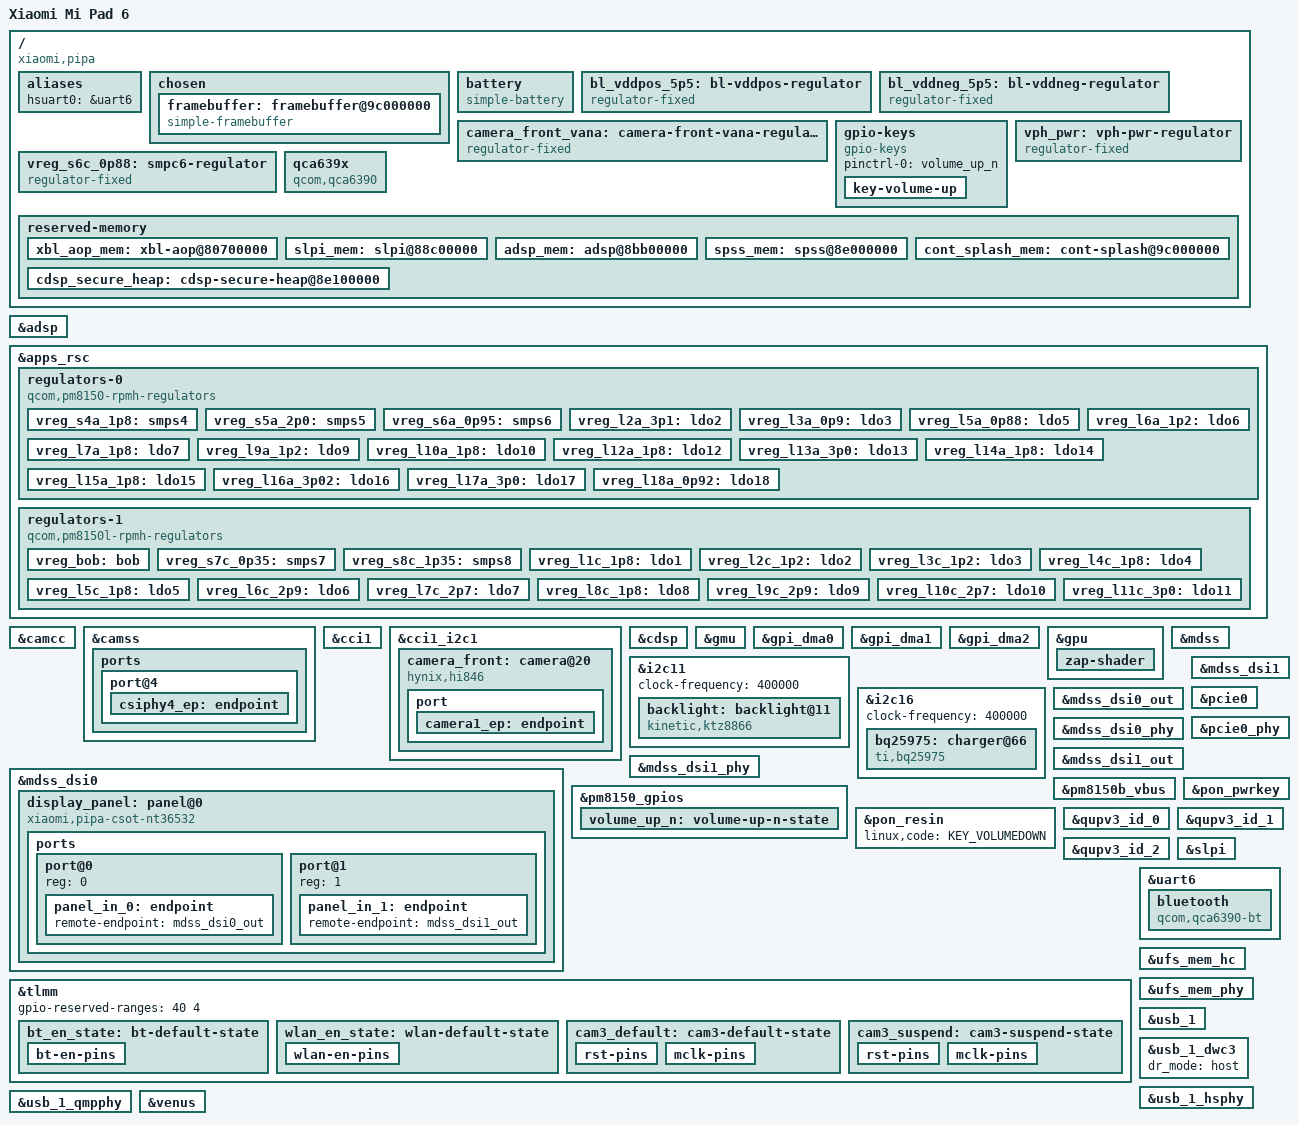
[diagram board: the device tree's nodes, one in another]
/dts-v1/;

#include <dt-bindings/arm/qcom,ids.h>
#include <dt-bindings/phy/phy.h>
#include <dt-bindings/regulator/qcom,rpmh-regulator.h>
#include <dt-bindings/usb/pd.h>
#include "sm8250ac.dtsi"
#include "pm8150.dtsi"
#include "pm8150b.dtsi"
#include "pm8150l.dtsi"

/*
 * Delete following upstream (sm8250.dtsi) reserved
 * memory mappings which are different on this device.
 */
/delete-node/ &adsp_mem;
/delete-node/ &cdsp_secure_heap;
/delete-node/ &slpi_mem;
/delete-node/ &spss_mem;
/delete-node/ &xbl_aop_mem;

/ {
	model = "Xiaomi Mi Pad 6";
	compatible = "xiaomi,pipa", "qcom,sm8250";
	classis-type = "tablet";

	/* required for bootloader to select correct board */
	qcom,msm-id = <QCOM_ID_SM8250 0x20001>; /* SM8250 v2.1 */
	qcom,board-id = <0x34 0>;

	aliases {
		hsuart0 = &uart6;
	};

	chosen {
		#address-cells = <2>;
		#size-cells = <2>;
		ranges;

		framebuffer: framebuffer@9c000000 {
			compatible = "simple-framebuffer";
			reg = <0x0 0x9c000000 0x0 0x2300000>;
			width = <1800>;
			height = <2880>;
			stride = <(1800 * 4)>;
			format = "a8r8g8b8";
		};
	};

	battery: battery {
		compatible = "simple-battery";
		device-chemistry = "lithium-ion-polymer";
		// voltage-min-design-microvolt = <3870000>;
		// energy-full-design-microwatt-hours = <16600000>;
		// charge-full-design-microamp-hours = <4300000>;
		constant-charge-current-max-microamp = <5900000>;
		constant-charge-voltage-max-microvolt = <4430000>;
	};

	bl_vddpos_5p5: bl-vddpos-regulator {
		compatible = "regulator-fixed";
		regulator-name = "bl_vddpos_5p5";
		regulator-min-microvolt = <5500000>;
		regulator-max-microvolt = <5500000>;
		regulator-enable-ramp-delay = <233>;
		gpio = <&tlmm 130 GPIO_ACTIVE_HIGH>;
		enable-active-high;
		regulator-boot-on;
	};

	bl_vddneg_5p5: bl-vddneg-regulator {
		compatible = "regulator-fixed";
		regulator-name = "bl_vddneg_5p5";
		regulator-min-microvolt = <5500000>;
		regulator-max-microvolt = <5500000>;
		regulator-enable-ramp-delay = <233>;
		gpio = <&tlmm 131 GPIO_ACTIVE_HIGH>;
		enable-active-high;
		regulator-boot-on;
	};

    camera_front_vana: camera-front-vana-regulator {
        compatible = "regulator-fixed";
        regulator-name = "camera_front_vana";
        regulator-min-microvolt = <2800000>;
        regulator-max-microvolt = <2800000>;
        regulator-enable-ramp-delay = <135>;
        enable-active-high;
        gpio = <&tlmm 84 0>;
    };

	gpio-keys {
		compatible = "gpio-keys";

		pinctrl-0 = <&volume_up_n>;
		pinctrl-names = "default";

		key-volume-up {
			label = "Volume Up";
			linux,code = <KEY_VOLUMEUP>;
			gpios = <&pm8150_gpios 6 GPIO_ACTIVE_LOW>;
			debounce-interval = <15>;
			linux,can-disable;
			wakeup-source;
		};
	};

	vph_pwr: vph-pwr-regulator {
		compatible = "regulator-fixed";
		regulator-name = "vph_pwr";
		regulator-min-microvolt = <3700000>;
		regulator-max-microvolt = <3700000>;
	};

	/* S6c is really ebi.lvl but it's there for supply map completeness sake. */
	vreg_s6c_0p88: smpc6-regulator {
		compatible = "regulator-fixed";
		regulator-name = "vreg_s6c_0p88";
		regulator-min-microvolt = <880000>;
		regulator-max-microvolt = <880000>;
		regulator-always-on;
		vin-supply = <&vph_pwr>;
	};

	qca639x: qca639x {
		compatible = "qcom,qca6390";
		#power-domain-cells = <0>;

		vddaon-supply = <&vreg_s6a_0p95>;
		vddpmu-supply = <&vreg_s6a_0p95>;
		vddrfa1-supply = <&vreg_s5a_2p0>;
		vddrfa2-supply = <&vreg_s8c_1p35>;
		vddrfa3-supply = <&vreg_s5a_2p0>;
		vddpcie1-supply = <&vreg_s8c_1p35>;
		vddpcie2-supply = <&vreg_s5a_2p0>;
		vddio-supply = <&vreg_s4a_1p8>;

		pinctrl-names = "default";
		pinctrl-0 = <&wlan_en_state>;

		wlan-en-gpios = <&tlmm 20 GPIO_ACTIVE_HIGH>;
	};

	reserved-memory {
		xbl_aop_mem: xbl-aop@80700000 {
			reg = <0x0 0x80600000 0x0 0x260000>;
			no-map;
		};

		slpi_mem: slpi@88c00000 {
			reg = <0x0 0x88c00000 0x0 0x2f00000>;
			no-map;
		};

		adsp_mem: adsp@8bb00000 {
			reg = <0x0 0x8bb00000 0x0 0x2500000>;
			no-map;
		};

		spss_mem: spss@8e000000 {
			reg = <0x0 0x8e000000 0x0 0x100000>;
			no-map;
		};

		cdsp_secure_heap: cdsp-secure-heap@8e100000 {
			reg = <0x0 0x8e100000 0x0 0x4600000>;
			no-map;
		};

		cont_splash_mem: cont-splash@9c000000 {
			reg = <0x0 0x9c000000 0x0 0x2300000>;
			no-map;
		};
	};
};

&adsp {
	firmware-name = "qcom/sm8250/xiaomi/pipa/adsp.mbn";
	status = "okay";
};

&apps_rsc {
	regulators-0 {
		compatible = "qcom,pm8150-rpmh-regulators";
		qcom,pmic-id = "a";

		vdd-s1-supply = <&vph_pwr>;
		vdd-s2-supply = <&vph_pwr>;
		vdd-s3-supply = <&vph_pwr>;
		vdd-s4-supply = <&vph_pwr>;
		vdd-s5-supply = <&vph_pwr>;
		vdd-s6-supply = <&vph_pwr>;
		vdd-s7-supply = <&vph_pwr>;
		vdd-s8-supply = <&vph_pwr>;
		vdd-s9-supply = <&vph_pwr>;
		vdd-s10-supply = <&vph_pwr>;
		vdd-l1-l8-l11-supply = <&vreg_s6c_0p88>;
		vdd-l2-l10-supply = <&vreg_bob>;
		vdd-l3-l4-l5-l18-supply = <&vreg_s6a_0p95>;
		vdd-l6-l9-supply = <&vreg_s8c_1p35>;
		vdd-l7-l12-l14-l15-supply = <&vreg_s5a_2p0>;
		vdd-l13-l16-l17-supply = <&vreg_bob>;

		/* (S1+S2+S3) - cx.lvl (ARC) */

		vreg_s4a_1p8: smps4 {
			regulator-name = "vreg_s4a_1p8";
			regulator-min-microvolt = <1800000>;
			regulator-max-microvolt = <1920000>;
			regulator-initial-mode = <RPMH_REGULATOR_MODE_HPM>;
			regulator-allow-set-load;
			regulator-allowed-modes = <RPMH_REGULATOR_MODE_LPM
						   RPMH_REGULATOR_MODE_HPM>;
		};

		vreg_s5a_2p0: smps5 {
			regulator-name = "vreg_s5a_2p0";
			regulator-min-microvolt = <2000000>;
			regulator-max-microvolt = <2040000>;
			regulator-initial-mode = <RPMH_REGULATOR_MODE_HPM>;
		};

		vreg_s6a_0p95: smps6 {
			regulator-name = "vreg_s6a_0p95";
			regulator-min-microvolt = <600000>;
			regulator-max-microvolt = <1128000>;
			regulator-initial-mode = <RPMH_REGULATOR_MODE_HPM>;
		};

		vreg_l2a_3p1: ldo2 {
			regulator-name = "vreg_l2a_3p1";
			regulator-min-microvolt = <3072000>;
			regulator-max-microvolt = <3072000>;
			regulator-initial-mode = <RPMH_REGULATOR_MODE_HPM>;
		};

		vreg_l3a_0p9: ldo3 {
			regulator-name = "vreg_l3a_0p9";
			regulator-min-microvolt = <928000>;
			regulator-max-microvolt = <932000>;
			regulator-initial-mode = <RPMH_REGULATOR_MODE_HPM>;
		};

		/* L4 - lmx.lvl (ARC) */

		vreg_l5a_0p88: ldo5 {
			regulator-name = "vreg_l5a_0p88";
			regulator-min-microvolt = <880000>;
			regulator-max-microvolt = <880000>;
			regulator-initial-mode = <RPMH_REGULATOR_MODE_HPM>;
		};

		vreg_l6a_1p2: ldo6 {
			regulator-name = "vreg_l6a_1p2";
			regulator-min-microvolt = <1200000>;
			regulator-max-microvolt = <1200000>;
			regulator-initial-mode = <RPMH_REGULATOR_MODE_HPM>;
			regulator-allow-set-load;
			regulator-allowed-modes = <RPMH_REGULATOR_MODE_LPM
						   RPMH_REGULATOR_MODE_HPM>;
		};

		vreg_l7a_1p8: ldo7 {
			regulator-name = "vreg_l7a_1p8";
			regulator-min-microvolt = <1704000>;
			regulator-max-microvolt = <1800000>;
			regulator-initial-mode = <RPMH_REGULATOR_MODE_HPM>;
		};

		vreg_l9a_1p2: ldo9 {
			regulator-name = "vreg_l9a_1p2";
			regulator-min-microvolt = <1200000>;
			regulator-max-microvolt = <1200000>;
			regulator-initial-mode = <RPMH_REGULATOR_MODE_HPM>;
		};

		vreg_l10a_1p8: ldo10 {
			regulator-name = "vreg_l10a_1p8";
			regulator-min-microvolt = <1800000>;
			regulator-max-microvolt = <2960000>;
			regulator-initial-mode = <RPMH_REGULATOR_MODE_HPM>;
		};

		/* L11 - lcx.lvl (ARC) */

		vreg_l12a_1p8: ldo12 {
			regulator-name = "vreg_l12a_1p8";
			regulator-min-microvolt = <1800000>;
			regulator-max-microvolt = <1800000>;
			regulator-initial-mode = <RPMH_REGULATOR_MODE_HPM>;
		};

		vreg_l13a_3p0: ldo13 {
			regulator-name = "vreg_l13a_3p0";
			regulator-min-microvolt = <3008000>;
			regulator-max-microvolt = <3008000>;
			regulator-initial-mode = <RPMH_REGULATOR_MODE_HPM>;
		};

		vreg_l14a_1p8: ldo14 {
			regulator-name = "vreg_l14a_1p8";
			regulator-min-microvolt = <1800000>;
			regulator-max-microvolt = <1880000>;
			regulator-initial-mode = <RPMH_REGULATOR_MODE_HPM>;
		};

		vreg_l15a_1p8: ldo15 {
			regulator-name = "vreg_l15a_1p8";
			regulator-min-microvolt = <1800000>;
			regulator-max-microvolt = <1800000>;
			regulator-initial-mode = <RPMH_REGULATOR_MODE_HPM>;
		};

		vreg_l16a_3p02: ldo16 {
			regulator-name = "vreg_l16a_3p02";
			regulator-min-microvolt = <3024000>;
			regulator-max-microvolt = <3304000>;
			regulator-initial-mode = <RPMH_REGULATOR_MODE_HPM>;
		};

		vreg_l17a_3p0: ldo17 {
			regulator-name = "vreg_l17a_3p0";
			regulator-min-microvolt = <2496000>;
			regulator-max-microvolt = <3008000>;
			regulator-initial-mode = <RPMH_REGULATOR_MODE_HPM>;
			regulator-allow-set-load;
			regulator-allowed-modes = <RPMH_REGULATOR_MODE_LPM
						   RPMH_REGULATOR_MODE_HPM>;
		};

		vreg_l18a_0p92: ldo18 {
			regulator-name = "vreg_l18a_0p92";
			regulator-min-microvolt = <800000>;
			regulator-max-microvolt = <920000>;
			regulator-initial-mode = <RPMH_REGULATOR_MODE_HPM>;
		};
	};

	regulators-1 {
		compatible = "qcom,pm8150l-rpmh-regulators";
		qcom,pmic-id = "c";

		vdd-s1-supply = <&vph_pwr>;
		vdd-s2-supply = <&vph_pwr>;
		vdd-s3-supply = <&vph_pwr>;
		vdd-s4-supply = <&vph_pwr>;
		vdd-s5-supply = <&vph_pwr>;
		vdd-s6-supply = <&vph_pwr>;
		vdd-s7-supply = <&vph_pwr>;
		vdd-s8-supply = <&vph_pwr>;
		vdd-l1-l8-supply = <&vreg_s4a_1p8>;
		vdd-l2-l3-supply = <&vreg_s8c_1p35>;
		vdd-l4-l5-l6-supply = <&vreg_bob>;
		vdd-l7-l11-supply = <&vreg_bob>;
		vdd-l9-l10-supply = <&vreg_bob>;
		vdd-bob-supply = <&vph_pwr>;

		vreg_bob: bob {
			regulator-name = "vreg_bob";
			regulator-min-microvolt = <3008000>;
			regulator-max-microvolt = <3960000>;
			regulator-initial-mode = <RPMH_REGULATOR_MODE_AUTO>;
		};

		/*
		 * S1-S6 are ARCs:
		 * (S1+S2) - gfx.lvl,
		 * S3 - mx.lvl,
		 * (S4+S5) - mmcx.lvl,
		 * S6 - ebi.lvl
		 */

		vreg_s7c_0p35: smps7 {
			regulator-name = "vreg_s7c_0p35";
			regulator-min-microvolt = <348000>;
			regulator-max-microvolt = <1000000>;
			regulator-initial-mode = <RPMH_REGULATOR_MODE_HPM>;
		};

		vreg_s8c_1p35: smps8 {
			regulator-name = "vreg_s8c_1p35";
			regulator-min-microvolt = <1200000>;
			regulator-max-microvolt = <1400000>;
			regulator-initial-mode = <RPMH_REGULATOR_MODE_HPM>;
		};

		vreg_l1c_1p8: ldo1 {
			regulator-name = "vreg_l1c_1p8";
			regulator-min-microvolt = <1800000>;
			regulator-max-microvolt = <1800000>;
			regulator-initial-mode = <RPMH_REGULATOR_MODE_HPM>;
		};

		vreg_l2c_1p2: ldo2 {
			regulator-name = "vreg_l2c_1p2";
			regulator-min-microvolt = <1200000>;
			regulator-max-microvolt = <1304000>;
			regulator-initial-mode = <RPMH_REGULATOR_MODE_HPM>;
		};

		vreg_l3c_1p2: ldo3 {
			regulator-name = "vreg_l3c_1p2";
			regulator-min-microvolt = <800000>;
			regulator-max-microvolt = <1200000>;
			regulator-initial-mode = <RPMH_REGULATOR_MODE_HPM>;
		};

		vreg_l4c_1p8: ldo4 {
			regulator-name = "vreg_l4c_1p8";
			regulator-min-microvolt = <1800000>;
			regulator-max-microvolt = <2800000>;
			regulator-initial-mode = <RPMH_REGULATOR_MODE_HPM>;
		};

		vreg_l5c_1p8: ldo5 {
			regulator-name = "vreg_l5c_1p8";
			regulator-min-microvolt = <1800000>;
			regulator-max-microvolt = <2800000>;
			regulator-initial-mode = <RPMH_REGULATOR_MODE_HPM>;
		};

		vreg_l6c_2p9: ldo6 {
			regulator-name = "vreg_l6c_2p9";
			regulator-min-microvolt = <1800000>;
			regulator-max-microvolt = <2960000>;
			regulator-initial-mode = <RPMH_REGULATOR_MODE_HPM>;
			regulator-allow-set-load;
			regulator-allowed-modes = <RPMH_REGULATOR_MODE_LPM
						   RPMH_REGULATOR_MODE_HPM>;
		};

		vreg_l7c_2p7: ldo7 {
			regulator-name = "vreg_l7c_2p7";
			regulator-min-microvolt = <2856000>;
			regulator-max-microvolt = <3104000>;
			regulator-initial-mode = <RPMH_REGULATOR_MODE_HPM>;
		};

		vreg_l8c_1p8: ldo8 {
			regulator-name = "vreg_l8c_1p8";
			regulator-min-microvolt = <1800000>;
			regulator-max-microvolt = <1800000>;
			regulator-initial-mode = <RPMH_REGULATOR_MODE_HPM>;
		};

		vreg_l9c_2p9: ldo9 {
			regulator-name = "vreg_l9c_2p9";
			regulator-min-microvolt = <2704000>;
			regulator-max-microvolt = <2960000>;
			regulator-initial-mode = <RPMH_REGULATOR_MODE_HPM>;
			regulator-allow-set-load;
			regulator-allowed-modes = <RPMH_REGULATOR_MODE_LPM
						   RPMH_REGULATOR_MODE_HPM>;
		};

		vreg_l10c_2p7: ldo10 {
			regulator-name = "vreg_l10c_2p7";
			regulator-min-microvolt = <3000000>;
			regulator-max-microvolt = <3312000>;
			regulator-initial-mode = <RPMH_REGULATOR_MODE_HPM>;
		};

		vreg_l11c_3p0: ldo11 {
			regulator-name = "vreg_l11c_3p0";
			regulator-min-microvolt = <3000000>;
			regulator-max-microvolt = <3000000>;
			regulator-initial-mode = <RPMH_REGULATOR_MODE_HPM>;
		};
	};
};

&camcc {
	status = "okay";
};

&camss {
	vdda-phy-supply = <&vreg_l5a_0p88>;
	vdda-pll-supply = <&vreg_l9a_1p2>;
	status = "okay";

	ports {
		/* The port index denotes CSIPHY id i.e. csiphy4 */
		port@4 {
			csiphy4_ep: endpoint {
				clock-lanes = <7>;
				data-lanes = <0 1>;
				remote-endpoint = <&camera1_ep>;
			};
		};
	};
};

&cci1 {
	assigned-clocks = <&camcc CAM_CC_CCI_1_CLK_SRC>,
						<&camcc CAM_CC_CCI_1_CLK>;
	assigned-clock-rates = <37500000>,
							<0>;

	status = "okay";
};

&cci1_i2c1 {
	camera_front: camera@20 {
		compatible = "hynix,hi846";
		reg = <0x20>;
		pinctrl-names = "default", "suspend";
		pinctrl-0 = <&cam3_default>;
		pinctrl-1 = <&cam3_suspend>;
		clocks = <&camcc CAM_CC_MCLK3_CLK>;
		assigned-clocks = <&camcc CAM_CC_MCLK3_CLK>;
		assigned-clock-rates = <19200000>;
		reset-gpios = <&tlmm 109 GPIO_ACTIVE_LOW>;
		vdda-supply = <&camera_front_vana>;
		vddd-supply = <&vreg_l2c_1p2>;
		vddio-supply = <&vreg_l1c_1p8>;
		rotation = <90>;
		orientation = <0>;

		port {
			camera1_ep: endpoint {
				clock-lanes = <0>;
				data-lanes = <1 2>;
				link-frequencies = /bits/ 64
					<80000000 200000000>;
				remote-endpoint = <&csiphy4_ep>;
			};
		};
	};

};

&cdsp {
	firmware-name = "qcom/sm8250/xiaomi/pipa/cdsp.mbn";
	status = "okay";
};

&gmu {
	status = "okay";
};

&gpi_dma0 {
	status = "okay";
};

&gpi_dma1 {
	status = "okay";
};

&gpi_dma2 {
	status = "okay";
};

&gpu {
	status = "okay";

	zap-shader {
		memory-region = <&gpu_mem>;
		firmware-name = "qcom/sm8250/xiaomi/pipa/a650_zap.mbn";
	};
};

&i2c11 {
	clock-frequency = <400000>;
	status = "okay";

	backlight: backlight@11 {
		compatible = "kinetic,ktz8866";
		reg = <0x11>;
		vddpos-supply = <&bl_vddpos_5p5>;
		vddneg-supply = <&bl_vddneg_5p5>;
		enable-gpios = <&tlmm 139 GPIO_ACTIVE_HIGH>;
		current-num-sinks = <5>;
		kinetic,current-ramp-delay-ms = <128>;
		kinetic,led-enable-ramp-delay-ms = <1>;
		kinetic,enable-lcd-bias;
	};
};

&i2c16 {
	clock-frequency = <400000>;
	status = "okay";

	bq25975: charger@66 {
		compatible = "ti,bq25975";
		reg = <0x66>;
		interrupt-parent = <&tlmm>;
		interrupts = <68 IRQ_TYPE_EDGE_FALLING>;
		ti,watchdog-timeout-ms = <0>;
		ti,sc-ocp-limit-microamp = <5750000>;
		ti,sc-ovp-limit-microvolt = <12000000>;
		monitored-battery = <&battery>;
	};
};

&mdss {
	status = "okay";
};

&mdss_dsi0 {
	vdda-supply = <&vreg_l9a_1p2>;
	qcom,dual-dsi-mode;
	qcom,sync-dual-dsi;
	qcom,master-dsi;
	status = "okay";

	display_panel: panel@0 {
		reg = <0>;
		// vddio-supply = <&vreg_l14a_1p88>;
		reset-gpios = <&tlmm 75 GPIO_ACTIVE_LOW>;
		backlight = <&backlight>;
		compatible = "xiaomi,pipa-csot-nt36532", "novatek,nt36532";
		status = "okay";

		ports {
			#address-cells = <1>;
			#size-cells = <0>;

			port@0 {
				reg = <0>;

				panel_in_0: endpoint {
					remote-endpoint = <&mdss_dsi0_out>;
				};
			};

			port@1 {
				reg = <1>;

				panel_in_1: endpoint {
					remote-endpoint = <&mdss_dsi1_out>;
				};
			};
		};
	};
};

&mdss_dsi0_out {
	data-lanes = <0 1 2 3>;
	remote-endpoint = <&panel_in_0>;
};

&mdss_dsi0_phy {
	vdds-supply = <&vreg_l5a_0p88>;
	phy-type = <PHY_TYPE_DPHY>;
	status = "okay";
};

&mdss_dsi1 {
	vdda-supply = <&vreg_l9a_1p2>;
	qcom,dual-dsi-mode;
	qcom,sync-dual-dsi;
	/* DSI1 is slave, so use DSI0 clocks */
	assigned-clock-parents = <&mdss_dsi0_phy 0>, <&mdss_dsi0_phy 1>;
	status = "okay";
};

&mdss_dsi1_out {
	data-lanes = <0 1 2 3>;
	remote-endpoint = <&panel_in_1>;
};

&mdss_dsi1_phy {
	vdds-supply = <&vreg_l5a_0p88>;
	phy-type = <PHY_TYPE_DPHY>;
	status = "okay";
};

&pcie0 {
	status = "okay";
};

&pcie0_phy {
	vdda-phy-supply = <&vreg_l5a_0p88>;
	vdda-pll-supply = <&vreg_l9a_1p2>;
	status = "okay";

	/* Power on QCA639x chip, otherwise PCIe bus timeouts */
	power-domains = <&qca639x>;
};

&pm8150_gpios {
	volume_up_n: volume-up-n-state {
		pins = "gpio6";
		function = "normal";
		power-source = <1>;
		bias-pull-up;
		input-enable;
	};
};

&pm8150b_vbus {
	regulator-min-microamp = <500000>;
	regulator-max-microamp = <3000000>;
	status = "okay";
};

&pon_pwrkey {
	status = "okay";
};

&pon_resin {
	linux,code = <KEY_VOLUMEDOWN>;
	status = "okay";
};

&qupv3_id_0 {
	status = "okay";
};

&qupv3_id_1 {
	status = "okay";
};

&qupv3_id_2 {
	status = "okay";
};

&slpi {
	firmware-name = "qcom/sm8250/xiaomi/pipa/slpi.mbn";
	status = "okay";
};

&tlmm {
	gpio-reserved-ranges = <40 4>;

	bt_en_state: bt-default-state {
		bt-en-pins {
			pins = "gpio21";
			function = "gpio";

			drive-strength = <16>;
			output-low;
			bias-pull-up;
		};
	};

	wlan_en_state: wlan-default-state {
		wlan-en-pins {
			pins = "gpio20";
			function = "gpio";

			drive-strength = <16>;
			output-low;
			bias-pull-up;
		};
	};

	cam3_default: cam3-default-state {
		rst-pins {
			pins = "gpio109", "gpio84";
			function = "gpio";
			drive-strength = <2>;
			bias-disable;
		};

		mclk-pins {
			pins = "gpio97";
			function = "cam_mclk";
			drive-strength = <4>;
			bias-disable;
		};
	};

	cam3_suspend: cam3-suspend-state {
		rst-pins {
			pins = "gpio109", "gpio84";
			function = "gpio";
			drive-strength = <2>;
			bias-pull-down;
			output-low;
		};

		mclk-pins {
			pins = "gpio97";
			function = "cam_mclk";
			drive-strength = <4>;
			bias-pull-down;
		};
	};

};

&uart6 {
	status = "okay";

	bluetooth {
		compatible = "qcom,qca6390-bt";
		pinctrl-names = "default";
		pinctrl-0 = <&bt_en_state>;

		power-domains = <&qca639x>;
		enable-gpios = <&tlmm 21 GPIO_ACTIVE_HIGH>;
	};
};

&ufs_mem_hc {
	status = "okay";

	vcc-supply = <&vreg_l17a_3p0>;
	vcc-max-microamp = <800000>;
	vccq-supply = <&vreg_l6a_1p2>;
	vccq-max-microamp = <800000>;
	vccq2-supply = <&vreg_s4a_1p8>;
	vccq2-max-microamp = <800000>;
};

&ufs_mem_phy {
	status = "okay";

	vdda-phy-supply = <&vreg_l5a_0p88>;
	vdda-pll-supply = <&vreg_l9a_1p2>;
};

&usb_1 {
	status = "okay";
};

&usb_1_dwc3 {
	dr_mode = "host";
};

&usb_1_hsphy {
	status = "okay";

	vdda-pll-supply = <&vreg_l5a_0p88>;
	vdda33-supply = <&vreg_l2a_3p1>;
	vdda18-supply = <&vreg_l12a_1p8>;
};

&usb_1_qmpphy {
	status = "okay";

	vdda-phy-supply = <&vreg_l9a_1p2>;
	vdda-pll-supply = <&vreg_l18a_0p92>;
    orientation-switch;
};

&venus {
	firmware-name = "qcom/sm8250/xiaomi/pipa/venus.mbn";
	status = "okay";
};
